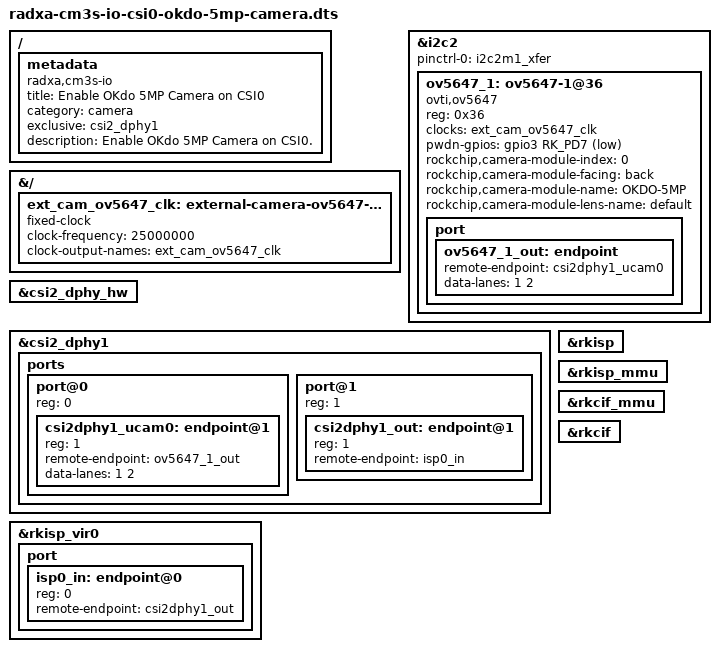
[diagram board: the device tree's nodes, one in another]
/dts-v1/;
/plugin/;

#include <dt-bindings/gpio/gpio.h>
#include <dt-bindings/pinctrl/rockchip.h>

/ {
	metadata {
		title = "Enable OKdo 5MP Camera on CSI0";
		compatible = "radxa,cm3s-io", "radxa,radxa-cm3-sodimm-io";
		category = "camera";
		exclusive = "csi2_dphy1";
		description = "Enable OKdo 5MP Camera on CSI0.";
	};
};

&{/} {
	ext_cam_ov5647_clk: external-camera-ov5647-clock {
		status = "okay";
		compatible = "fixed-clock";
		clock-frequency = <25000000>;
		clock-output-names = "ext_cam_ov5647_clk";
		#clock-cells = <0>;
	};
};

&i2c2 {
	status = "okay";
	pinctrl-names = "default";
	pinctrl-0 = <&i2c2m1_xfer>;
	#address-cells = <1>;
	#size-cells = <0>;

	ov5647_1: ov5647-1@36 {
		status = "okay";
		compatible = "ovti,ov5647";
		reg = <0x36>;
		clocks = <&ext_cam_ov5647_clk>;
		clock-names = "ext_cam_ov5647_clk";
		pwdn-gpios = <&gpio3 RK_PD7 GPIO_ACTIVE_LOW>;
		rockchip,camera-module-index = <0>;
		rockchip,camera-module-facing = "back";
		rockchip,camera-module-name = "OKDO-5MP";
		rockchip,camera-module-lens-name = "default";

		port {
			ov5647_1_out: endpoint {
				remote-endpoint = <&csi2dphy1_ucam0>;
				data-lanes = <1 2>;
			};
		};
	};
};

&csi2_dphy_hw {
	status = "okay";
};

&csi2_dphy1 {
	status = "okay";

	ports {
		#address-cells = <1>;
		#size-cells = <0>;

		port@0 {
			reg = <0>;
			#address-cells = <1>;
			#size-cells = <0>;

			csi2dphy1_ucam0: endpoint@1 {
				reg = <1>;
				remote-endpoint = <&ov5647_1_out>;
				data-lanes = <1 2>;
			};
		};

		port@1 {
			reg = <1>;
			#address-cells = <1>;
			#size-cells = <0>;

			csi2dphy1_out: endpoint@1 {
				reg = <1>;
				remote-endpoint = <&isp0_in>;
			};
		};
	};
};

&rkisp_vir0 {
	status = "okay";

	port {
		#address-cells = <1>;
		#size-cells = <0>;

		isp0_in: endpoint@0 {
			reg = <0>;
			remote-endpoint = <&csi2dphy1_out>;
		};
	};
};

&rkisp {
	status = "okay";
};

&rkisp_mmu {
	status = "okay";
};

&rkcif_mmu {
	status = "okay";
};

&rkcif {
	status = "okay";
};
